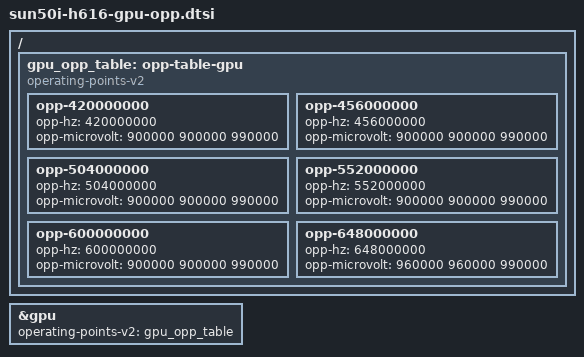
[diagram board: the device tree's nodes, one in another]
// SPDX-License-Identifier: (GPL-2.0+ OR MIT)
// Copyright (C) 2022 Clément Péron <peron.clem@gmail.com>

/ {
	gpu_opp_table: opp-table-gpu {
		compatible = "operating-points-v2";

		opp-420000000 {
			opp-hz = /bits/ 64 <420000000>;
			opp-microvolt = <900000 900000 990000>;
		};

		opp-456000000 {
			opp-hz = /bits/ 64 <456000000>;
			opp-microvolt = <900000 900000 990000>;
		};

		opp-504000000 {
			opp-hz = /bits/ 64 <504000000>;
			opp-microvolt = <900000 900000 990000>;
		};

		opp-552000000 {
			opp-hz = /bits/ 64 <552000000>;
			opp-microvolt = <900000 900000 990000>;
		};

		opp-600000000 {
			opp-hz = /bits/ 64 <600000000>;
			opp-microvolt = <900000 900000 990000>;
		};

		opp-648000000 {
			opp-hz = /bits/ 64 <648000000>;
			opp-microvolt = <960000 960000 990000>;
		};
	};
};

&gpu {
	operating-points-v2 = <&gpu_opp_table>;
};
